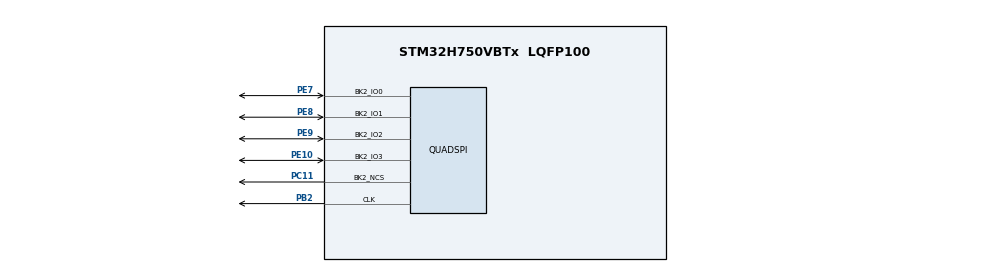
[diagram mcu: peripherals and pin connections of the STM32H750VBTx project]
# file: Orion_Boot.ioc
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CORTEX_M7.CPU_DCache=Enabled
CORTEX_M7.CPU_ICache=Enabled
Mcu.Family=STM32H7
Mcu.Name=STM32H750VBTx
Mcu.Package=LQFP100
NVIC.PriorityGroup=NVIC_PRIORITYGROUP_4
NVIC.QUADSPI_IRQn=true\:0\:0\:false\:false\:true\:true\:true\:true
PB2.GPIO_Speed=GPIO_SPEED_FREQ_VERY_HIGH
PB2.Mode=Single Bank 2
PB2.Signal=QUADSPI_CLK
PC11.GPIO_Speed=GPIO_SPEED_FREQ_VERY_HIGH
PC11.Mode=Single Bank 2
PC11.Signal=QUADSPI_BK2_NCS
PE10.GPIO_Speed=GPIO_SPEED_FREQ_VERY_HIGH
PE10.Mode=Single Bank 2
PE10.Signal=QUADSPI_BK2_IO3
PE7.GPIO_Speed=GPIO_SPEED_FREQ_VERY_HIGH
PE7.Mode=Single Bank 2
PE7.Signal=QUADSPI_BK2_IO0
PE8.GPIO_Speed=GPIO_SPEED_FREQ_VERY_HIGH
PE8.Mode=Single Bank 2
PE8.Signal=QUADSPI_BK2_IO1
PE9.GPIO_Speed=GPIO_SPEED_FREQ_VERY_HIGH
PE9.Mode=Single Bank 2
PE9.Signal=QUADSPI_BK2_IO2
PH0-OSC_IN\ (PH0).Mode=HSE-External-Oscillator
PH0-OSC_IN\ (PH0).Signal=RCC_OSC_IN
PH1-OSC_OUT\ (PH1).Mode=HSE-External-Oscillator
PH1-OSC_OUT\ (PH1).Signal=RCC_OSC_OUT
ProjectManager.HeapSize=0x200
ProjectManager.StackSize=0x400
ProjectManager.TargetToolchain=STM32CubeIDE
QUADSPI.ChipSelectHighTime=QSPI_CS_HIGH_TIME_1_CYCLE
QUADSPI.ClockMode=QSPI_CLOCK_MODE_3
QUADSPI.ClockPrescaler=1
QUADSPI.FifoThreshold=4
QUADSPI.FlashSize=23
QUADSPI.SampleShifting=QSPI_SAMPLE_SHIFTING_HALFCYCLE
RCC.ADCFreq_Value=96750000
RCC.APB1Freq_Value=120000000
RCC.APB2Freq_Value=120000000
RCC.APB3Freq_Value=120000000
RCC.APB4Freq_Value=120000000
RCC.CortexFreq_Value=480000000
RCC.D1PPRE=RCC_APB3_DIV2
RCC.D2PPRE1=RCC_APB1_DIV2
RCC.D2PPRE2=RCC_APB2_DIV2
RCC.D3PPRE=RCC_APB4_DIV2
RCC.DIVM1=3
RCC.DIVN1=60
RCC.HCLKFreq_Value=240000000
RCC.HPRE=RCC_HCLK_DIV2
RCC.HSE_VALUE=48000000
RCC.PLLSourceVirtual=RCC_PLLSOURCE_HSE
RCC.SYSCLKFreq_VALUE=480000000
RCC.SYSCLKSource=RCC_SYSCLKSOURCE_PLLCLK
RCC.USBFreq_Value=480000000
board=custom

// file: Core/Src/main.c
/* USER CODE BEGIN Header */
/**
  ******************************************************************************
  * @file           : main.c
  * @brief          : Main program body
  ******************************************************************************
  * @attention
  *
  * Copyright (c) 2022 STMicroelectronics.
  * All rights reserved.
  *
  * This software is licensed under terms that can be found in the LICENSE file
  * in the root directory of this software component.
  * If no LICENSE file comes with this software, it is provided AS-IS.
  *
  ******************************************************************************
  */
/* USER CODE END Header */
#include "main.h"
#include "quadspi.h"
#include "gpio.h"

void SystemClock_Config(void);

/* USER CODE BEGIN 0 */
typedef void (*pFunction)(void);
pFunction JumpToApplication;

#define APPLICATION_ADDRESS 0x90000000
/* USER CODE END 0 */

int main(void)
{

  /* Enable I-Cache---------------------------------------------------------*/
  SCB_EnableICache();

  /* Enable D-Cache---------------------------------------------------------*/
  SCB_EnableDCache();

  /* MCU Configuration--------------------------------------------------------*/

  /* Reset of all peripherals, Initializes the Flash interface and the Systick. */
  HAL_Init();

  /* Configure the system clock */
  SystemClock_Config();

  /* Initialize all configured peripherals */
  MX_GPIO_Init();
  MX_QUADSPI_Init();

  /* USER CODE BEGIN 2 */
  if (CSP_QUADSPI_Init() != HAL_OK) {
    Error_Handler();
  }

  if (CSP_QSPI_EnableMemoryMappedMode() != HAL_OK) {
    Error_Handler();
  }

  SCB_DisableDCache();
  SCB_DisableICache();
  SysTick->CTRL = 0;

  JumpToApplication = (pFunction) (*(__IO uint32_t*) (APPLICATION_ADDRESS + 4));
  __set_MSP(*(__IO uint32_t*) APPLICATION_ADDRESS);
  JumpToApplication();

  /* USER CODE END 2 */

  /* Infinite loop */
  while (1)
  {

  }
}

void SystemClock_Config(void)
{
  RCC_OscInitTypeDef RCC_OscInitStruct = {0};
  RCC_ClkInitTypeDef RCC_ClkInitStruct = {0};

  /** Supply configuration update enable
  */
  HAL_PWREx_ConfigSupply(PWR_LDO_SUPPLY);

  /** Configure the main internal regulator output voltage
  */
  __HAL_PWR_VOLTAGESCALING_CONFIG(PWR_REGULATOR_VOLTAGE_SCALE1);

  while(!__HAL_PWR_GET_FLAG(PWR_FLAG_VOSRDY)) {}

  __HAL_RCC_SYSCFG_CLK_ENABLE();
  __HAL_PWR_VOLTAGESCALING_CONFIG(PWR_REGULATOR_VOLTAGE_SCALE0);

  while(!__HAL_PWR_GET_FLAG(PWR_FLAG_VOSRDY)) {}

  /** Initializes the RCC Oscillators according to the specified parameters
  * in the RCC_OscInitTypeDef structure.
  */
  RCC_OscInitStruct.OscillatorType = RCC_OSCILLATORTYPE_HSE;
  RCC_OscInitStruct.HSEState = RCC_HSE_ON;
  RCC_OscInitStruct.PLL.PLLState = RCC_PLL_ON;
  RCC_OscInitStruct.PLL.PLLSource = RCC_PLLSOURCE_HSE;
  RCC_OscInitStruct.PLL.PLLM = 3;
  RCC_OscInitStruct.PLL.PLLN = 60;
  RCC_OscInitStruct.PLL.PLLP = 2;
  RCC_OscInitStruct.PLL.PLLQ = 2;
  RCC_OscInitStruct.PLL.PLLR = 2;
  RCC_OscInitStruct.PLL.PLLRGE = RCC_PLL1VCIRANGE_3;
  RCC_OscInitStruct.PLL.PLLVCOSEL = RCC_PLL1VCOWIDE;
  RCC_OscInitStruct.PLL.PLLFRACN = 0;
  if (HAL_RCC_OscConfig(&RCC_OscInitStruct) != HAL_OK)
  {
    Error_Handler();
  }

  /** Initializes the CPU, AHB and APB buses clocks
  */
  RCC_ClkInitStruct.ClockType = RCC_CLOCKTYPE_HCLK|RCC_CLOCKTYPE_SYSCLK
                              |RCC_CLOCKTYPE_PCLK1|RCC_CLOCKTYPE_PCLK2
                              |RCC_CLOCKTYPE_D3PCLK1|RCC_CLOCKTYPE_D1PCLK1;
  RCC_ClkInitStruct.SYSCLKSource = RCC_SYSCLKSOURCE_PLLCLK;
  RCC_ClkInitStruct.SYSCLKDivider = RCC_SYSCLK_DIV1;
  RCC_ClkInitStruct.AHBCLKDivider = RCC_HCLK_DIV2;
  RCC_ClkInitStruct.APB3CLKDivider = RCC_APB3_DIV2;
  RCC_ClkInitStruct.APB1CLKDivider = RCC_APB1_DIV2;
  RCC_ClkInitStruct.APB2CLKDivider = RCC_APB2_DIV2;
  RCC_ClkInitStruct.APB4CLKDivider = RCC_APB4_DIV2;

  if (HAL_RCC_ClockConfig(&RCC_ClkInitStruct, FLASH_LATENCY_4) != HAL_OK)
  {
    Error_Handler();
  }
}

void Error_Handler(void)
{
  __disable_irq();
  while (1)
  {
  }
}
